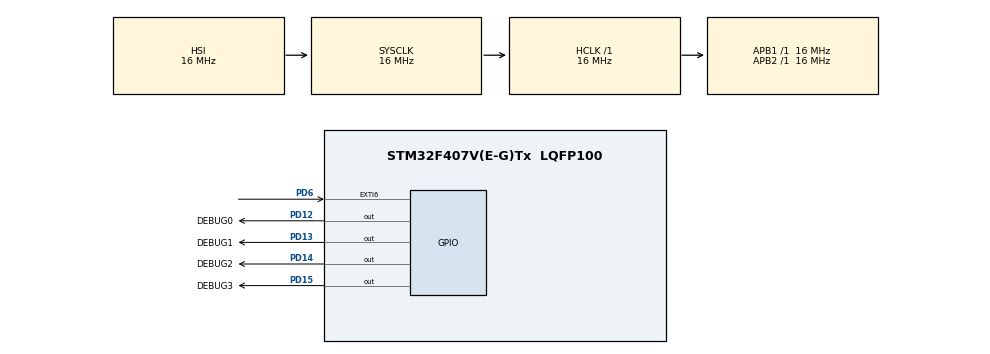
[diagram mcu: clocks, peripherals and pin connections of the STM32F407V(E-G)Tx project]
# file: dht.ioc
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Mcu.Family=STM32F4
Mcu.Name=STM32F407V(E-G)Tx
Mcu.Package=LQFP100
NVIC.EXTI9_5_IRQn=true\:0\:0\:false\:false\:true\:true\:true
NVIC.PriorityGroup=NVIC_PRIORITYGROUP_4
NVIC.TIM2_IRQn=true\:0\:0\:false\:false\:true\:true\:true
PA13.Mode=Serial_Wire
PA13.Signal=SYS_JTMS-SWDIO
PA14.Mode=Serial_Wire
PA14.Signal=SYS_JTCK-SWCLK
PD12.GPIO_Label=DEBUG0
PD12.Signal=GPIO_Output
PD13.GPIO_Label=DEBUG1
PD13.Signal=GPIO_Output
PD14.GPIO_Label=DEBUG2
PD14.Signal=GPIO_Output
PD15.GPIO_Label=DEBUG3
PD15.Signal=GPIO_Output
PD6.GPIO_ModeDefaultEXTI=GPIO_MODE_IT_RISING_FALLING
PD6.Signal=GPXTI6
ProjectManager.HeapSize=0x200
ProjectManager.StackSize=0x400
ProjectManager.TargetToolchain=STM32CubeIDE
RCC.AHBFreq_Value=16000000
RCC.APB1Freq_Value=16000000
RCC.APB2Freq_Value=16000000
RCC.CortexFreq_Value=16000000
RCC.HSE_VALUE=25000000
RCC.HSI_VALUE=16000000
RCC.LSE_VALUE=32768
RCC.SYSCLKFreq_VALUE=16000000
RCC.VCOOutputFreq_Value=192000000
TIM2.AutoReloadPreload=TIM_AUTORELOAD_PRELOAD_ENABLE
TIM2.Prescaler=15
VP_TIM2_VS_ClockSourceINT.Mode=Internal
board=custom

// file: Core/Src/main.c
/* USER CODE BEGIN Header */
/**
  ******************************************************************************
  * @file           : main.c
  * @brief          : Main program body
  ******************************************************************************
  * @attention
  *
  * <h2><center>&copy; Copyright (c) 2021 STMicroelectronics.
  * All rights reserved.</center></h2>
  *
  * This software component is licensed by ST under BSD 3-Clause license,
  * the "License"; You may not use this file except in compliance with the
  * License. You may obtain a copy of the License at:
  *                        opensource.org/licenses/BSD-3-Clause
  *
  ******************************************************************************
  */
/* USER CODE END Header */
#include "main.h"

/* USER CODE BEGIN Includes */
#include "DHT.h"
/* USER CODE END Includes */

TIM_HandleTypeDef htim2;

/* USER CODE BEGIN PV */
float temp = 0, humid = 0;
/* USER CODE END PV */

void SystemClock_Config(void);
static void MX_GPIO_Init(void);
static void MX_TIM2_Init(void);

/* USER CODE BEGIN 0 */
void HAL_GPIO_EXTI_Callback(uint16_t GPIO_Pin) {
	DHT_EXTI();
}
/* USER CODE END 0 */

int main(void)
{

  /* MCU Configuration--------------------------------------------------------*/

  /* Reset of all peripherals, Initializes the Flash interface and the Systick. */
  HAL_Init();

  /* Configure the system clock */
  SystemClock_Config();

  /* Initialize all configured peripherals */
  MX_GPIO_Init();
  MX_TIM2_Init();
  /* USER CODE BEGIN 2 */
  DHT_init(&htim2); // will be delay
  /* USER CODE END 2 */

  /* Infinite loop */
  /* USER CODE BEGIN WHILE */

  while (1)
  {
//	  HAL_GPIO_TogglePin(DEBUG0_GPIO_Port, DEBUG0_Pin);
//	  DHT_delay_us(500000);
	  DHT_read();
	  temp = DHT_getTemperature();
	  humid = DHT_getHumidity();
	  HAL_Delay(2000);

    /* USER CODE END WHILE */

  }
}

void SystemClock_Config(void)
{
  RCC_OscInitTypeDef RCC_OscInitStruct = {0};
  RCC_ClkInitTypeDef RCC_ClkInitStruct = {0};

  /** Configure the main internal regulator output voltage
  */
  __HAL_RCC_PWR_CLK_ENABLE();
  __HAL_PWR_VOLTAGESCALING_CONFIG(PWR_REGULATOR_VOLTAGE_SCALE1);
  /** Initializes the RCC Oscillators according to the specified parameters
  * in the RCC_OscInitTypeDef structure.
  */
  RCC_OscInitStruct.OscillatorType = RCC_OSCILLATORTYPE_HSI;
  RCC_OscInitStruct.HSIState = RCC_HSI_ON;
  RCC_OscInitStruct.HSICalibrationValue = RCC_HSICALIBRATION_DEFAULT;
  RCC_OscInitStruct.PLL.PLLState = RCC_PLL_NONE;
  if (HAL_RCC_OscConfig(&RCC_OscInitStruct) != HAL_OK)
  {
    Error_Handler();
  }
  /** Initializes the CPU, AHB and APB buses clocks
  */
  RCC_ClkInitStruct.ClockType = RCC_CLOCKTYPE_HCLK|RCC_CLOCKTYPE_SYSCLK
                              |RCC_CLOCKTYPE_PCLK1|RCC_CLOCKTYPE_PCLK2;
  RCC_ClkInitStruct.SYSCLKSource = RCC_SYSCLKSOURCE_HSI;
  RCC_ClkInitStruct.AHBCLKDivider = RCC_SYSCLK_DIV1;
  RCC_ClkInitStruct.APB1CLKDivider = RCC_HCLK_DIV1;
  RCC_ClkInitStruct.APB2CLKDivider = RCC_HCLK_DIV1;

  if (HAL_RCC_ClockConfig(&RCC_ClkInitStruct, FLASH_LATENCY_0) != HAL_OK)
  {
    Error_Handler();
  }
}

static void MX_TIM2_Init(void)
{

  TIM_ClockConfigTypeDef sClockSourceConfig = {0};
  TIM_MasterConfigTypeDef sMasterConfig = {0};

  htim2.Instance = TIM2;
  htim2.Init.Prescaler = 15;
  htim2.Init.CounterMode = TIM_COUNTERMODE_UP;
  htim2.Init.Period = 4294967295;
  htim2.Init.ClockDivision = TIM_CLOCKDIVISION_DIV1;
  htim2.Init.AutoReloadPreload = TIM_AUTORELOAD_PRELOAD_ENABLE;
  if (HAL_TIM_Base_Init(&htim2) != HAL_OK)
  {
    Error_Handler();
  }
  sClockSourceConfig.ClockSource = TIM_CLOCKSOURCE_INTERNAL;
  if (HAL_TIM_ConfigClockSource(&htim2, &sClockSourceConfig) != HAL_OK)
  {
    Error_Handler();
  }
  sMasterConfig.MasterOutputTrigger = TIM_TRGO_RESET;
  sMasterConfig.MasterSlaveMode = TIM_MASTERSLAVEMODE_DISABLE;
  if (HAL_TIMEx_MasterConfigSynchronization(&htim2, &sMasterConfig) != HAL_OK)
  {
    Error_Handler();
  }

}

static void MX_GPIO_Init(void)
{
  GPIO_InitTypeDef GPIO_InitStruct = {0};

  /* GPIO Ports Clock Enable */
  __HAL_RCC_GPIOD_CLK_ENABLE();
  __HAL_RCC_GPIOA_CLK_ENABLE();

  /*Configure GPIO pin Output Level */
  HAL_GPIO_WritePin(GPIOD, DEBUG0_Pin|DEBUG1_Pin|DEBUG2_Pin|DEBUG3_Pin, GPIO_PIN_RESET);

  /*Configure GPIO pins : DEBUG0_Pin DEBUG1_Pin DEBUG2_Pin DEBUG3_Pin */
  GPIO_InitStruct.Pin = DEBUG0_Pin|DEBUG1_Pin|DEBUG2_Pin|DEBUG3_Pin;
  GPIO_InitStruct.Mode = GPIO_MODE_OUTPUT_PP;
  GPIO_InitStruct.Pull = GPIO_NOPULL;
  GPIO_InitStruct.Speed = GPIO_SPEED_FREQ_LOW;
  HAL_GPIO_Init(GPIOD, &GPIO_InitStruct);

  /*Configure GPIO pin : PD6 */
  GPIO_InitStruct.Pin = GPIO_PIN_6;
  GPIO_InitStruct.Mode = GPIO_MODE_IT_RISING_FALLING;
  GPIO_InitStruct.Pull = GPIO_NOPULL;
  HAL_GPIO_Init(GPIOD, &GPIO_InitStruct);

  /* EXTI interrupt init*/
  HAL_NVIC_SetPriority(EXTI9_5_IRQn, 0, 0);
  HAL_NVIC_EnableIRQ(EXTI9_5_IRQn);

}

void Error_Handler(void)
{
  __disable_irq();
  while (1)
  {
  }
}

/************************ (C) COPYRIGHT STMicroelectronics *****END OF FILE****/
